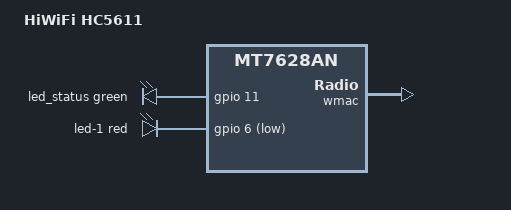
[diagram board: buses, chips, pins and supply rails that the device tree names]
// SPDX-License-Identifier: GPL-2.0-or-later OR MIT

#include "mt7628an_hiwifi_hc5x61a.dtsi"

/ {
	compatible = "hiwifi,hc5611", "mediatek,mt7628an-soc";
	model = "HiWiFi HC5611";

	aliases {
		label-mac-device = &ethernet;
		led-boot = &led_status;
		led-failsafe = &led_status;
		led-running = &led_status;
		led-upgrade = &led_status;
	};

	leds {
		compatible = "gpio-leds";

		led_status: led-0 {
			color = <LED_COLOR_ID_GREEN>;
			function = LED_FUNCTION_STATUS;
			gpios = <&gpio 11 GPIO_ACTIVE_HIGH>;
			default-state = "on";
		};

		led-1 {
			color = <LED_COLOR_ID_RED>;
			function = LED_FUNCTION_WAN;
			gpios = <&gpio 6 GPIO_ACTIVE_LOW>;
		};
	};
};

/*
 * All MAC addresses are derived from the label MAC. label + 1 is reserved
 * for the wan address, derive label + 2 for the radio so that it does not
 * share its MAC with the single ethernet port.
 */
&wmac {
	nvmem-cells = <&eeprom_factory_0>, <&macaddr_bdinfo_18a 2>;
	nvmem-cell-names = "eeprom", "mac-address";
};

&state_default {
	gpio {
		groups = "gpio", "spi cs1", "wdt";
		function = "gpio";
	};
};
